# Polarfire SoC register map
Vendor: Microchip; File version: 1.0
CPU: Microchip PolarFire SoC 1.0, little endian
Registers are 32-bit, read-write, reset 0x0 unless marked. A register's access mark holds for its fields unless they carry their own. Offsets are from the block's base; [hi:lo] are bit positions; {n}, {i} and the like mark numbered series; 'fields as' and 'values as' point back to an identical list.

## GPIO_IOBANK0_LO — GPIO_IOBANK0_LO Controller
Base 0x20120000
Same registers: GPIO_IOBANK1_LO 0x20121000, GPIO_FAB_LO 0x20122000, GPIO_IOBANK0_HI 0x28120000, GPIO_IOBANK1_HI 0x28121000, GPIO_FAB_HI 0x28122000
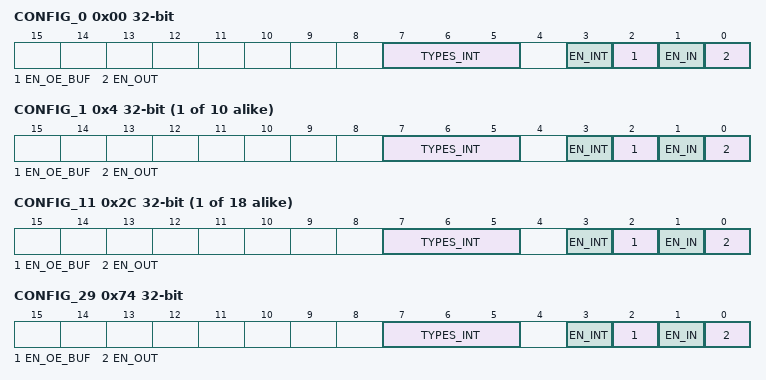
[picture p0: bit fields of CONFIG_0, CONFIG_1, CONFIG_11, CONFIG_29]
0x00 CONFIG_0
  [7:5] TYPES_INT — Interrupt Types. 000: Level High, 001: Level Low, 010: Edge Positive, 011: Edge Negative, 100: Edge Both
  [3] EN_INT — Interrupt Enable
  [2] EN_OE_BUF — Output Buffer Enable
  [1] EN_IN — Input reg enable
  [0] EN_OUT — Output reg enable
{0x0+4i} CONFIG_{i} (i=1..10)
  [7:5] TYPES_INT — Same as CONFIG_0
  [3] EN_INT — Same as CONFIG_0
  [2] EN_OE_BUF — Same as CONFIG_0
  [1] EN_IN — Same as CONFIG_0
  [0] EN_OUT — Same as CONFIG_0
{0x0+4i} CONFIG_{i} (i=11..28) — Same as CONFIG_0
  [7:5] TYPES_INT, [3] EN_INT, [2] EN_OE_BUF, [1] EN_IN, [0] EN_OUT
0x74 CONFIG_29
  [7:5] TYPES_INT, [3] EN_INT, [2] EN_OE_BUF, [1] EN_IN, [0] EN_OUT
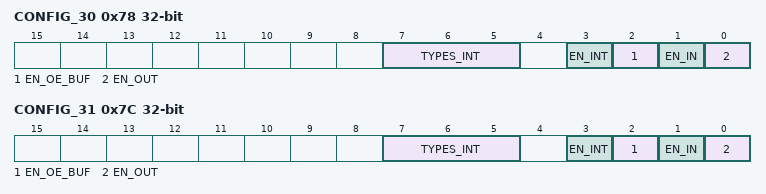
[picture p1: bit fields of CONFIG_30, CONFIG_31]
0x78 CONFIG_30 — Same as CONFIG_0
  [7:5] TYPES_INT, [3] EN_INT, [2] EN_OE_BUF, [1] EN_IN, [0] EN_OUT
0x7C CONFIG_31 — Same as CONFIG_0
  fields as CONFIG_1
0x80 INTR
  [0] NO_FIELD_NAMES_OR_BIT_RANGES_ASSIGNED_YET — Per bit interrupt, ; Read Modify Write. To clear an interrtupt the bit is written with '1'
0x84 GPIN ro
  [31:0] NO_FIELD_NAMES_OR_BIT_RANGES_ASSIGNED_YET — Read-only for input configured ports.
0x88 GPOUT
  [31:0] NO_FIELD_NAMES_OR_BIT_RANGES_ASSIGNED_YET — Writeable/Readable for output configured ports; don't care for input configured ports
0x8C CONFIG_ALL
  [0] CONFIG_ALL — set all configs
{0x90+4i} CONFIG_BYTE{i} (i=0..3)
  [0] CONFIG_BYTE{i} — Set all configs in byte 0
0xA0 CLEAR_BITS ro
  [31:0] CLEAR_BITS rw — Writing a '1' to a bit will clear that bit in the GPIO register. Other bits hold value.
0xA4 SET_BITS ro
  [31:0] SET_BITS rw — Writing a '1' to a bit will set that bit in the GPIO register. Other bits hold value.

## H2FINT_LO — H2FINT_LO Controller
Base 0x20126000
Same registers: H2FINT_HI 0x28126000
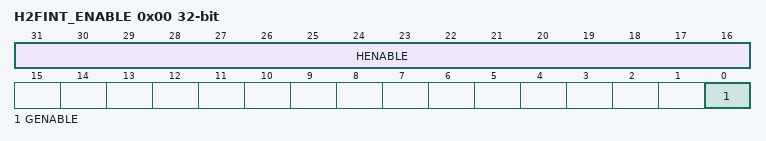
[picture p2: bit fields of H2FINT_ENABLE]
0x00 H2FINT_ENABLE
  [31:16] HENABLE — Enables individual H2F outputs
  [0] GENABLE — Enables all the H2FINT outputs
0x04 H2FSTATUS ro
  [15:0] H2FSTATUS — Read back of the 16-bit H2F Interrupts before the H2F and global enable
0x10 PLSTATUS0 ro
  [31:0] PLSTATUS0 — Indicates that the PLINT interrupt is active before the PLINT enable i.e. direct read of the PLINT inputs [31:0]
0x14 PLSTATUS1 ro
  [31:0] PLSTATUS1 — Indicates that the PLIT interrupt is active before the PLINT enable i.e. direct read of the PLINT inputs [63:32]
0x18 PLSTATUS2 ro
  [31:0] PLSTATUS2 — Indicates that the PLIT interrupt is active before the PLINT enable i.e. direct read of the PLINT inputs [95:64]
0x1C PLSTATUS3 ro
  [31:0] PLSTATUS3 — Indicates that the PLINT interrupt is active before the PLINT enable i.e. direct read of the PLINT inputs [127:96]
{0x20+4i} PLENABLE{i} (i=0..3)
  [31:0] PLENABLE{i} — Enables PLINT interrupts {32i+31}:{32i}

## CRYPTO — CRYPTO Controller
Base 0x20127000
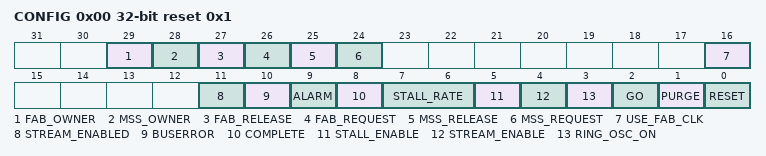
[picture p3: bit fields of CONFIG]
0x00 CONFIG reset 0x1
  [29] FAB_OWNER ro — Fabric controls the crypto block
  [28] MSS_OWNER ro — MSS controls the crypto block
  [27] FAB_RELEASE ro — Fabric has released the crypto, see the MSS/Fabric Crypto block ownership section in the MAS specification
  [26] FAB_REQUEST — Fabric is requesting crypto use, see the MSS/Fabric Crypto block ownership section in the MAS specification
  [25] MSS_RELEASE ro — MSS releases crypto, see the MSS/Fabric Crypto block ownership section in the MAS specification
  [24] MSS_REQUEST — MSS requests crypto use, see the MSS/Fabric Crypto block ownership section in the MAS specification
  [16] USE_FAB_CLK — When '1' in MSS mode the Crypto core and AHB interconnect is clocked by the Fabric clock rather than by the MSS sourced 200MHz clock source. This allows the MSS to use the AHB interfaces and the Fabric the streaming interface.
  [11] STREAM_ENABLED ro — Indicates that the streaming interface ie enabled
  [10] BUSERROR ro — Status signal from Athena core indicating it received a AHB bus error response
  [9] ALARM ro — Status signal from Athena core indicating alarm condition
  [8] COMPLETE ro — Status signal from Athena core indicating complete
  [7:6] STALL_RATE — Sets the average stall rate. 00: 1 in 8 01: 1 in 16 10: 1 in 32 11: 1 in 64
  [5] STALL_ENABLE — Enables the stall system on the Crypto core 0: Operates in G5 mode using fabric stall signal, clock_select must be 01 1: Internal mode enabled, stall occurrence generated internally on average 1 in 8 clocks. Works with clock_select 01 or 11.
  [4] STREAM_ENABLE — Enables the streaming interface to the fabric, must also be enabled via SCB device register
  [3] RING_OSC_ON — Turns on the Athena ring oscillators, note turned off at reset
  [2] GO — Asserts the Athena go input
  [1] PURGE — Asserts the Athena purge command input
  [0] RESET — Asserts the internal Athena core reset signal
0x04 STALL
  [31:0] SEED — Sets the seed value used in the generation off the Athena Stall logic
0x08 UPPER_ADDRESS
  [5:0] ADDRESS — Sets the upper 6-bits of the 38 bit Master address provided to the MSS.
